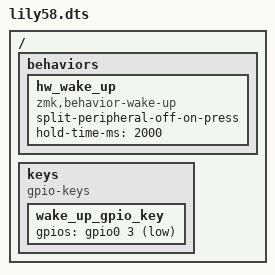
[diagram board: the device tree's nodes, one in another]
/ {
    behaviors {
        hw_wake_up: hw_wake_up {
            compatible = "zmk,behavior-wake-up";
            split-peripheral-off-on-press;
            hold-time-ms = <2000>; // Hold for 2 seconds to wake up
        };
    };

    keys {
        compatible = "gpio-keys";
        wake_up_gpio_key: wake_up_gpio_key {
            gpios = <&gpio0 3 (GPIO_ACTIVE_LOW | GPIO_PULL_UP)>;
        };
    };

}
